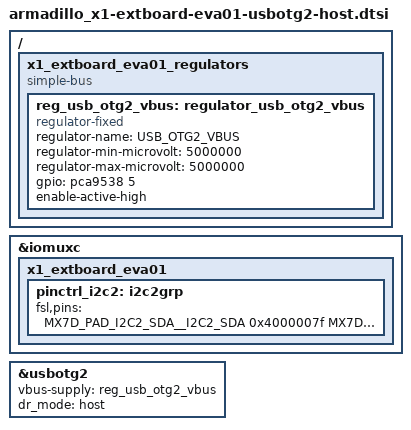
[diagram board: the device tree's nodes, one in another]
// SPDX-License-Identifier: GPL-2.0
/*
 * Copyright (C) 2024 Atmark Techno, Inc. All Rights Reserved.
 */

/ {
	x1_extboard_eva01_regulators {
		compatible = "simple-bus";
		#address-cells = <1>;
		#size-cells = <0>;

		reg_usb_otg2_vbus: regulator_usb_otg2_vbus {
			compatible = "regulator-fixed";
			regulator-name = "USB_OTG2_VBUS";
			regulator-min-microvolt = <5000000>;
			regulator-max-microvolt = <5000000>;
			gpio = <&pca9538 5 GPIO_ACTIVE_HIGH>;
			enable-active-high;
		};
	};
};

&iomuxc {
	x1_extboard_eva01 {
		pinctrl_i2c2: i2c2grp {
			fsl,pins = <
				MX7D_PAD_I2C2_SDA__I2C2_SDA	0x4000007f
				MX7D_PAD_I2C2_SCL__I2C2_SCL	0x4000007f
			>;
		};
	};
};

&usbotg2 {
	vbus-supply = <&reg_usb_otg2_vbus>;
	dr_mode = "host";
	status = "okay";
};
